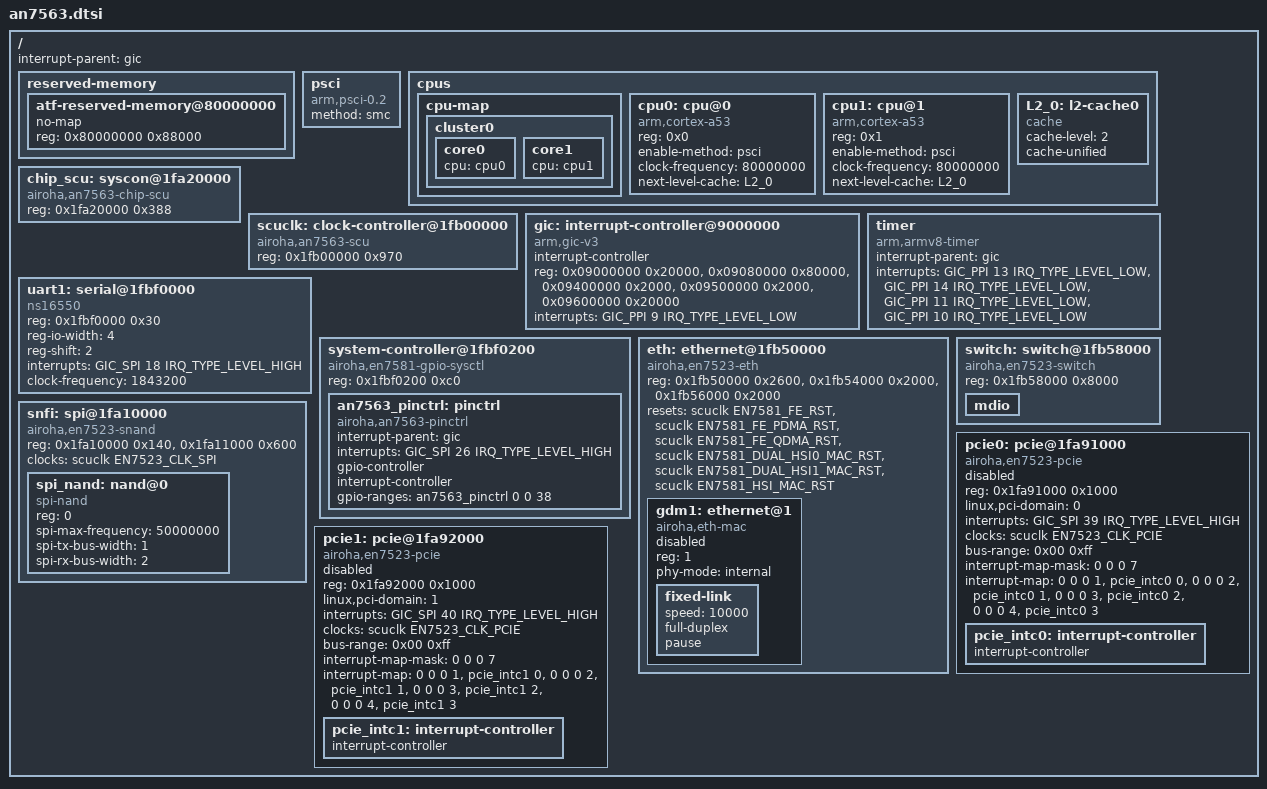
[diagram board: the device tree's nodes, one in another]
// SPDX-License-Identifier: (GPL-2.0-only OR BSD-2-Clause)
/*
 * Airoha AN7563 / AN7552 SoC dtsi.
 *
 * AN7563 is a dual Cortex-A53 cluster running ARMv8 in 32-bit AArch32
 * mode (ARMv7-A code path) but its chip-SCU and SCU register windows
 * follow the EN7581 layout, in particular the IOMUX_1 register at
 * chip-SCU offset 0x214 which differs from EN7523 (0x210).
 *
 * The two SCU nodes therefore carry an AN7563-specific compatible
 * followed by the EN7581 fallback compatibles, which is what
 * clk-airoha / reset-airoha and the AN7563 mach-airoha glue match
 * against to share the EN7581 clock / reset descriptor tables.
 */

#include <dt-bindings/interrupt-controller/irq.h>
#include <dt-bindings/interrupt-controller/arm-gic.h>
#include <dt-bindings/gpio/gpio.h>
#include <dt-bindings/clock/en7523-clk.h>
#include <dt-bindings/reset/airoha,en7581-reset.h>

/ {
	interrupt-parent = <&gic>;
	#address-cells = <1>;
	#size-cells = <1>;

	reserved-memory {
		#address-cells = <1>;
		#size-cells = <1>;
		ranges;

		atf-reserved-memory@80000000 {
			no-map;
			reg = <0x80000000 0x88000>;
		};
	};

	psci {
		compatible = "arm,psci-0.2";
		method = "smc";
	};

	cpus {
		#address-cells = <1>;
		#size-cells = <0>;

		cpu-map {
			cluster0 {
				core0 {
					cpu = <&cpu0>;
				};
				core1 {
					cpu = <&cpu1>;
				};
			};
		};

		cpu0: cpu@0 {
			device_type = "cpu";
			compatible = "arm,cortex-a53";
			reg = <0x0>;
			enable-method = "psci";
			clock-frequency = <80000000>;
			next-level-cache = <&L2_0>;
		};

		cpu1: cpu@1 {
			device_type = "cpu";
			compatible = "arm,cortex-a53";
			reg = <0x1>;
			enable-method = "psci";
			clock-frequency = <80000000>;
			next-level-cache = <&L2_0>;
		};

		L2_0: l2-cache0 {
			compatible = "cache";
			cache-level = <2>;
			cache-unified;
		};
	};

	chip_scu: syscon@1fa20000 {
		compatible = "airoha,an7563-chip-scu",
			     "airoha,en7581-chip-scu",
			     "syscon";
		reg = <0x1fa20000 0x388>;
	};

	scuclk: clock-controller@1fb00000 {
		compatible = "airoha,an7563-scu",
			     "airoha,en7581-scu",
			     "syscon";
		reg = <0x1fb00000 0x970>;
		#clock-cells = <1>;
		#reset-cells = <1>;
	};

	gic: interrupt-controller@9000000 {
		compatible = "arm,gic-v3";
		interrupt-controller;
		#interrupt-cells = <3>;
		#address-cells = <1>;
		#size-cells = <1>;
		reg = <0x09000000 0x20000>,
		      <0x09080000 0x80000>,
		      <0x09400000 0x2000>,
		      <0x09500000 0x2000>,
		      <0x09600000 0x20000>;
		interrupts = <GIC_PPI 9 IRQ_TYPE_LEVEL_LOW>;
	};

	timer {
		compatible = "arm,armv8-timer";
		interrupt-parent = <&gic>;
		interrupts = <GIC_PPI 13 IRQ_TYPE_LEVEL_LOW>,
			     <GIC_PPI 14 IRQ_TYPE_LEVEL_LOW>,
			     <GIC_PPI 11 IRQ_TYPE_LEVEL_LOW>,
			     <GIC_PPI 10 IRQ_TYPE_LEVEL_LOW>;
	};

	uart1: serial@1fbf0000 {
		compatible = "ns16550";
		reg = <0x1fbf0000 0x30>;
		reg-io-width = <4>;
		reg-shift = <2>;
		interrupts = <GIC_SPI 18 IRQ_TYPE_LEVEL_HIGH>;
		clock-frequency = <1843200>;
		bootph-all;
		status = "okay";
	};

	system-controller@1fbf0200 {
		compatible = "airoha,en7581-gpio-sysctl", "syscon",
			     "simple-mfd";
		reg = <0x1fbf0200 0xc0>;

		an7563_pinctrl: pinctrl {
			compatible = "airoha,an7563-pinctrl";

			interrupt-parent = <&gic>;
			interrupts = <GIC_SPI 26 IRQ_TYPE_LEVEL_HIGH>;

			gpio-controller;
			#gpio-cells = <2>;

			interrupt-controller;
			#interrupt-cells = <2>;

			gpio-ranges = <&an7563_pinctrl 0 0 38>;
		};
	};

	eth: ethernet@1fb50000 {
		compatible = "airoha,en7523-eth";
		reg = <0x1fb50000 0x2600>,
		      <0x1fb54000 0x2000>,
		      <0x1fb56000 0x2000>;
		reg-names = "fe", "qdma0", "qdma1";

		resets = <&scuclk EN7581_FE_RST>,
			 <&scuclk EN7581_FE_PDMA_RST>,
			 <&scuclk EN7581_FE_QDMA_RST>,
			 <&scuclk EN7581_DUAL_HSI0_MAC_RST>,
			 <&scuclk EN7581_DUAL_HSI1_MAC_RST>,
			 <&scuclk EN7581_HSI_MAC_RST>;
		reset-names = "fe", "pdma", "qdma",
			      "hsi0-mac", "hsi1-mac", "hsi-mac";

		#address-cells = <1>;
		#size-cells = <0>;

		gdm1: ethernet@1 {
			compatible = "airoha,eth-mac";
			reg = <1>;
			phy-mode = "internal";
			status = "disabled";

			fixed-link {
				speed = <10000>;
				full-duplex;
				pause;
			};
		};
	};

	switch: switch@1fb58000 {
		compatible = "airoha,en7523-switch";
		reg = <0x1fb58000 0x8000>;

		mdio: mdio {
			#address-cells = <1>;
			#size-cells = <0>;
		};
	};

	snfi: spi@1fa10000 {
		compatible = "airoha,en7523-snand", "airoha,en7581-snand";
		reg = <0x1fa10000 0x140>,
		      <0x1fa11000 0x600>;

		clocks = <&scuclk EN7523_CLK_SPI>;
		clock-names = "spi";

		#address-cells = <1>;
		#size-cells = <0>;

		spi_nand: nand@0 {
			compatible = "spi-nand";
			reg = <0>;
			spi-max-frequency = <50000000>;
			spi-tx-bus-width = <1>;
			spi-rx-bus-width = <2>;
		};
	};

	pcie0: pcie@1fa91000 {
		compatible = "airoha,en7523-pcie", "mediatek,mt7622-pcie";
		device_type = "pci";
		reg = <0x1fa91000 0x1000>;
		reg-names = "port0";
		linux,pci-domain = <0>;
		#address-cells = <3>;
		#size-cells = <2>;
		interrupts = <GIC_SPI 39 IRQ_TYPE_LEVEL_HIGH>;
		interrupt-names = "pcie_irq";
		clocks = <&scuclk EN7523_CLK_PCIE>;
		clock-names = "sys_ck0";
		bus-range = <0x00 0xff>;
		ranges = <0x82000000 0 0x20000000  0x20000000  0 0x8000000>;
		status = "disabled";

		#interrupt-cells = <1>;
		interrupt-map-mask = <0 0 0 7>;
		interrupt-map = <0 0 0 1 &pcie_intc0 0>,
				<0 0 0 2 &pcie_intc0 1>,
				<0 0 0 3 &pcie_intc0 2>,
				<0 0 0 4 &pcie_intc0 3>;
		pcie_intc0: interrupt-controller {
			interrupt-controller;
			#address-cells = <0>;
			#interrupt-cells = <1>;
		};
	};

	pcie1: pcie@1fa92000 {
		compatible = "airoha,en7523-pcie", "mediatek,mt7622-pcie";
		device_type = "pci";
		reg = <0x1fa92000 0x1000>;
		reg-names = "port1";
		linux,pci-domain = <1>;
		#address-cells = <3>;
		#size-cells = <2>;
		interrupts = <GIC_SPI 40 IRQ_TYPE_LEVEL_HIGH>;
		interrupt-names = "pcie_irq";
		clocks = <&scuclk EN7523_CLK_PCIE>;
		clock-names = "sys_ck1";
		bus-range = <0x00 0xff>;
		ranges = <0x82000000 0 0x28000000  0x28000000  0 0x8000000>;
		status = "disabled";

		#interrupt-cells = <1>;
		interrupt-map-mask = <0 0 0 7>;
		interrupt-map = <0 0 0 1 &pcie_intc1 0>,
				<0 0 0 2 &pcie_intc1 1>,
				<0 0 0 3 &pcie_intc1 2>,
				<0 0 0 4 &pcie_intc1 3>;
		pcie_intc1: interrupt-controller {
			interrupt-controller;
			#address-cells = <0>;
			#interrupt-cells = <1>;
		};
	};
};
